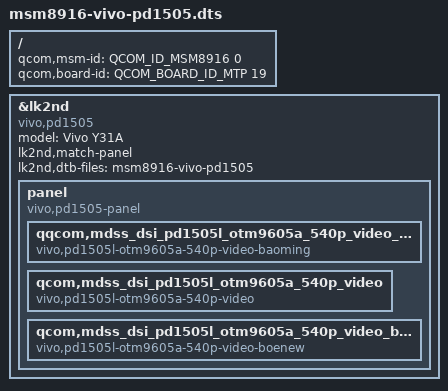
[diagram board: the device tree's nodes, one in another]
// SPDX-License-Identifier: BSD-3-Clause

#include <skeleton64.dtsi>
#include <lk2nd.dtsi>

/ {
	qcom,msm-id = <QCOM_ID_MSM8916 0>;
	qcom,board-id = <QCOM_BOARD_ID_MTP 19>;
};

&lk2nd {
	model = "Vivo Y31A";
	compatible = "vivo,pd1505";
	lk2nd,match-panel;

	lk2nd,dtb-files = "msm8916-vivo-pd1505";

panel {
		compatible = "vivo,pd1505-panel", "lk2nd,panel";

		qqcom,mdss_dsi_pd1505l_otm9605a_540p_video_baoming {
			compatible = "vivo,pd1505l-otm9605a-540p-video-baoming";
		};
		qcom,mdss_dsi_pd1505l_otm9605a_540p_video {
			compatible = "vivo,pd1505l-otm9605a-540p-video";
		};
		qcom,mdss_dsi_pd1505l_otm9605a_540p_video_boenew {
			compatible = "vivo,pd1505l-otm9605a-540p-video-boenew";
		};
	};
};
